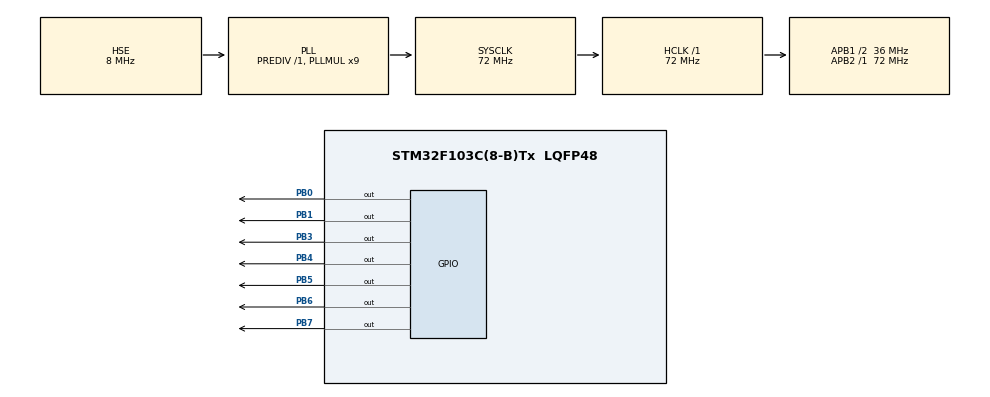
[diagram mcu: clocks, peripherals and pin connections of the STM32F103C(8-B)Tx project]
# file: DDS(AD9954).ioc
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Mcu.Family=STM32F1
Mcu.Name=STM32F103C(8-B)Tx
Mcu.Package=LQFP48
NVIC.PriorityGroup=NVIC_PRIORITYGROUP_4
PA13.Mode=Serial_Wire
PA13.Signal=SYS_JTMS-SWDIO
PA14.Mode=Serial_Wire
PA14.Signal=SYS_JTCK-SWCLK
PB0.PinState=GPIO_PIN_SET
PB0.Signal=GPIO_Output
PB1.PinState=GPIO_PIN_SET
PB1.Signal=GPIO_Output
PB3.PinState=GPIO_PIN_SET
PB3.Signal=GPIO_Output
PB4.PinState=GPIO_PIN_SET
PB4.Signal=GPIO_Output
PB5.PinState=GPIO_PIN_SET
PB5.Signal=GPIO_Output
PB6.PinState=GPIO_PIN_SET
PB6.Signal=GPIO_Output
PB7.PinState=GPIO_PIN_SET
PB7.Signal=GPIO_Output
PC14-OSC32_IN.Mode=LSE-External-Oscillator
PC14-OSC32_IN.Signal=RCC_OSC32_IN
PC15-OSC32_OUT.Mode=LSE-External-Oscillator
PC15-OSC32_OUT.Signal=RCC_OSC32_OUT
PD0-OSC_IN.Mode=HSE-External-Oscillator
PD0-OSC_IN.Signal=RCC_OSC_IN
PD1-OSC_OUT.Mode=HSE-External-Oscillator
PD1-OSC_OUT.Signal=RCC_OSC_OUT
ProjectManager.HeapSize=0x200
ProjectManager.StackSize=0x400
ProjectManager.TargetToolchain=MDK-ARM V5
RCC.AHBFreq_Value=72000000
RCC.APB1CLKDivider=RCC_HCLK_DIV2
RCC.APB1Freq_Value=36000000
RCC.APB1TimFreq_Value=72000000
RCC.APB2Freq_Value=72000000
RCC.APB2TimFreq_Value=72000000
RCC.HCLKFreq_Value=72000000
RCC.PLLMUL=RCC_PLL_MUL9
RCC.PLLSourceVirtual=RCC_PLLSOURCE_HSE
RCC.SYSCLKFreq_VALUE=72000000
RCC.SYSCLKSource=RCC_SYSCLKSOURCE_PLLCLK
RCC.USBFreq_Value=72000000
board=custom

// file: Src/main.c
/* USER CODE BEGIN Header */
/**
  ******************************************************************************
  * @file           : main.c
  * @brief          : Main program body
  ******************************************************************************
  * @attention
  *
  * <h2><center>&copy; Copyright (c) 2019 STMicroelectronics.
  * All rights reserved.</center></h2>
  *
  * This software component is licensed by ST under BSD 3-Clause license,
  * the "License"; You may not use this file except in compliance with the
  * License. You may obtain a copy of the License at:
  *                        opensource.org/licenses/BSD-3-Clause
  *
  ******************************************************************************
  */
/* USER CODE END Header */

#include "main.h"
#include "gpio.h"

/* USER CODE BEGIN Includes */
#include "DDS9954.h"
/* USER CODE END Includes */

void SystemClock_Config(void);

/* USER CODE BEGIN 0 */

//	void AD9954_RESET(void){
//		HAL_GPIO_WritePin(GPIOB,GPIO_PIN_6,GPIO_PIN_RESET);
//		HAL_GPIO_WritePin(GPIOB,GPIO_PIN_6,GPIO_PIN_SET);
//		delay_us(100);
//		HAL_GPIO_WritePin(GPIOB,GPIO_PIN_6,GPIO_PIN_RESET);
//		HAL_GPIO_WritePin(GPIOB,GPIO_PIN_5,GPIO_PIN_RESET);
//		HAL_GPIO_WritePin(GPIOB,GPIO_PIN_4,GPIO_PIN_RESET);
//		HAL_GPIO_WritePin(GPIOB,GPIO_PIN_0,GPIO_PIN_RESET);
//		HAL_GPIO_WritePin(GPIOB,GPIO_PIN_1,GPIO_PIN_RESET);
//		HAL_GPIO_WritePin(GPIOB,GPIO_PIN_7,GPIO_PIN_RESET);
//	}
//
//	void AD9954_SendByte(uint8_t data){
//		uint8_t i;
//		for(i=0;i<8;i++){
//			HAL_GPIO_WritePin(GPIOB,GPIO_PIN_4,GPIO_PIN_RESET); //SCLK = 0;
//			if( data & 0x80)
//			{
//				HAL_GPIO_WritePin(GPIOB,GPIO_PIN_3,GPIO_PIN_SET); //SDIO = 1;
//			}
//			else
//			{
//				HAL_GPIO_WritePin(GPIOB,GPIO_PIN_3,GPIO_PIN_RESET); //SDIO = 0;
//			}
//			HAL_GPIO_WritePin(GPIOB,GPIO_PIN_4,GPIO_PIN_SET); //SCLK = 1;
//			data <<= 1;
//		}
//	}
//
//	void UPDATE(void){
//		HAL_GPIO_WritePin(GPIOB,GPIO_PIN_7,GPIO_PIN_SET); //UPD = 1;
//		HAL_GPIO_WritePin(GPIOB,GPIO_PIN_7,GPIO_PIN_RESET); //UPD = 0;
//	}
//
//	void AD9954_Init(void){
//		HAL_GPIO_WritePin(GPIOB,GPIO_PIN_4,GPIO_PIN_RESET); //SCLK = 0;
//		HAL_GPIO_WritePin(GPIOB,GPIO_PIN_6,GPIO_PIN_RESET); //RES = 0;
//		HAL_GPIO_WritePin(GPIOB,GPIO_PIN_7,GPIO_PIN_RESET); //UPD = 0;
//		HAL_GPIO_WritePin(GPIOB,GPIO_PIN_0,GPIO_PIN_RESET); //PS0 = 0;
//		HAL_GPIO_WritePin(GPIOB,GPIO_PIN_1,GPIO_PIN_RESET); //PS1 = 0;
//		HAL_GPIO_WritePin(GPIOB,GPIO_PIN_5,GPIO_PIN_RESET); //CS = 0;
//		delay_us(1);
//		AD9954_SendByte(0x00);
//		AD9954_SendByte(0x00);
//		AD9954_SendByte(0x00);
//		AD9954_SendByte(0x00);
//		AD9954_SendByte(0x40);
//		AD9954_SendByte(0x01);
//		AD9954_SendByte(0x00);
//		AD9954_SendByte(0x00);
//		AD9954_SendByte(0x24);
//	}
//
//	void AD9954_SetFre(float f){
//		uint32_t date;
////		f*=5;
//		HAL_GPIO_WritePin(GPIOB,GPIO_PIN_5,GPIO_PIN_RESET); //CS = 0;
////		date=(uint32_t)(10.7374*f);
//		date=(uint32_t)(53.6715*f);
//		AD9954_SendByte(0x04);
//		AD9954_SendByte((uint8_t)(date>>24));
//		AD9954_SendByte((uint8_t)(date>>16));
//		AD9954_SendByte((uint8_t)(date>>8));
//		AD9954_SendByte((uint8_t)date);
//		UPDATE();
//	}
//
//	void AD9954_LinearSweep(float f1,float f2){
//		uint32_t date;
//		HAL_GPIO_WritePin(GPIOB,GPIO_PIN_4,GPIO_PIN_RESET); //SCLK = 0;
//		HAL_GPIO_WritePin(GPIOB,GPIO_PIN_6,GPIO_PIN_RESET); //RES = 0;
//		HAL_GPIO_WritePin(GPIOB,GPIO_PIN_7,GPIO_PIN_RESET); //UPD = 0;
//		HAL_GPIO_WritePin(GPIOB,GPIO_PIN_0,GPIO_PIN_RESET); //PS0 = 0;
//		HAL_GPIO_WritePin(GPIOB,GPIO_PIN_1,GPIO_PIN_RESET); //PS1 = 0;
//		HAL_GPIO_WritePin(GPIOB,GPIO_PIN_5,GPIO_PIN_RESET); //CS = 0;
//		AD9954_SendByte(0x00);
//		AD9954_SendByte(0x00);
//		AD9954_SendByte(0x20);
//		AD9954_SendByte(0x00);
//		AD9954_SendByte(0x40);
//		AD9954_SendByte(0x01);
//		AD9954_SendByte(0x00);
//		AD9954_SendByte(0x00);
//		AD9954_SendByte(0x24);
//		date = 53.6715*f1;
//		AD9954_SendByte(0x04);
//		AD9954_SendByte((uint8_t)(date>>24));
//		AD9954_SendByte((uint8_t)(date>>16));
//		AD9954_SendByte((uint8_t)(date>>8));
//		AD9954_SendByte((uint8_t)date);
//		date = 53.6715*f2;
//		AD9954_SendByte(0x06);
//		AD9954_SendByte((uint8_t)(date>>24));
//		AD9954_SendByte((uint8_t)(date>>16));
//		AD9954_SendByte((uint8_t)(date>>8));
//		AD9954_SendByte((uint8_t)date);
//		AD9954_SendByte(0x07);
//		AD9954_SendByte(0x01);
//		AD9954_SendByte(0x00);
//		AD9954_SendByte(0x00);
//		AD9954_SendByte(0x1b);
//		AD9954_SendByte(0xf4);
//		AD9954_SendByte(0x08);
//		AD9954_SendByte(0x01);
//		AD9954_SendByte(0x00);
//		AD9954_SendByte(0x01);
//		AD9954_SendByte(0xa3);
//		AD9954_SendByte(0x6f);
//		HAL_GPIO_WritePin(GPIOB,GPIO_PIN_5,GPIO_PIN_SET); //CS = 1;
//		UPDATE();
//	}
/* USER CODE END 0 */

int main(void)
{

  /* MCU Configuration--------------------------------------------------------*/

  /* Reset of all peripherals, Initializes the Flash interface and the Systick. */
  HAL_Init();

  /* Configure the system clock */
  SystemClock_Config();

  /* Initialize all configured peripherals */
  MX_GPIO_Init();
  /* USER CODE BEGIN 2 */
	AD9954_RESET();
	AD9954_Init();
	AD9954_SETFRE((uint32_t)150000000);
  /* USER CODE END 2 */

  /* Infinite loop */
  while (1)
  {

  }
}

void SystemClock_Config(void)
{
  RCC_OscInitTypeDef RCC_OscInitStruct = {0};
  RCC_ClkInitTypeDef RCC_ClkInitStruct = {0};

  /** Initializes the CPU, AHB and APB busses clocks
  */
  RCC_OscInitStruct.OscillatorType = RCC_OSCILLATORTYPE_HSE;
  RCC_OscInitStruct.HSEState = RCC_HSE_ON;
  RCC_OscInitStruct.HSEPredivValue = RCC_HSE_PREDIV_DIV1;
  RCC_OscInitStruct.HSIState = RCC_HSI_ON;
  RCC_OscInitStruct.PLL.PLLState = RCC_PLL_ON;
  RCC_OscInitStruct.PLL.PLLSource = RCC_PLLSOURCE_HSE;
  RCC_OscInitStruct.PLL.PLLMUL = RCC_PLL_MUL9;
  if (HAL_RCC_OscConfig(&RCC_OscInitStruct) != HAL_OK)
  {
    Error_Handler();
  }
  /** Initializes the CPU, AHB and APB busses clocks
  */
  RCC_ClkInitStruct.ClockType = RCC_CLOCKTYPE_HCLK|RCC_CLOCKTYPE_SYSCLK
                              |RCC_CLOCKTYPE_PCLK1|RCC_CLOCKTYPE_PCLK2;
  RCC_ClkInitStruct.SYSCLKSource = RCC_SYSCLKSOURCE_PLLCLK;
  RCC_ClkInitStruct.AHBCLKDivider = RCC_SYSCLK_DIV1;
  RCC_ClkInitStruct.APB1CLKDivider = RCC_HCLK_DIV2;
  RCC_ClkInitStruct.APB2CLKDivider = RCC_HCLK_DIV1;

  if (HAL_RCC_ClockConfig(&RCC_ClkInitStruct, FLASH_LATENCY_2) != HAL_OK)
  {
    Error_Handler();
  }
}

void Error_Handler(void)
{
}

/************************ (C) COPYRIGHT STMicroelectronics *****END OF FILE****/
